# AE402FA0E5597LE0_CM55_HP_View register map
Vendor: Alif Semiconductor; Series: E4; File version: 1.0
CPU: CM55 r1p0, selectable endian, MPU, FPU, double-precision FPU, DSP, VTOR, 8 interrupt priority bits, 1 SAU regions
Registers are 32-bit, read-write, reset 0x0 unless marked. A register's access mark holds for its fields unless they carry their own. Offsets are from the block's base; [hi:lo] are bit positions.

## SDMMC (part 1 of 2)
Base 0x48102000
0x00 SDMMC_SDMASA_R — SDMA System Address Register
  [31:0] BLOCKCNT_SDMASA — 32-bit Block Count-SDMA System Address. SDMMC_HOST_CTRL2_R[HOST_VER4_ENABLE] = 0x0: The BLOCKCNT_SDMASA bit field contains the system memory address for an SDMA transfer in the 32-bit addressing Mode. When the host controller stops an SDMA transfer, this bit field points to the system address of the next contiguous data position. It can be accessed only if no transaction is executing. Reading this bit field during data transfers may return invalid value. 32-bit Block Count SDMMC_HOST_CTRL2_R[HOST_VER4_ENABLE] = 0x1: From the host controller version 4.10 specification, the BLOCKCNT_SDMASA bit field is redefined as 32-bit Block Count. The host controller decrements the block count of this bit field for every block transfer and the data transfer stops when the count reaches zero. This bit field must be accessed when no transaction is executing. Reading this bit field during data transfers may return invalid value. Note: For the SDMMC_HOST_CTRL2_R[HOST_VER4_ENABLE] = 0x0, the host driver does not program the system address in this bit field while operating in ADMA mode. The system address must be programmed in the ADMA System Address register (SDMMC_ADMA_SA_LOW_R). For the SDMMC_HOST_CTRL2_R[HOST_VER4_ENABLE] = 0x0, the host driver programs a non-zero 32-bit block count value in this bit field when Auto CMD23 is enabled for non-DMA and ADMA modes. Auto CMD23 cannot be used with SDMA. This bit field must be programmed with a non-zero value for data transfer if the 32-bit Block Count register is used instead of the 16-bit Block Count register (SDMMC_BLOCKCOUNT_R).
    0xFFFFFFFF=4GB-1 Block; 2=2 Blocks; 1=1 Block; 0=Stop count
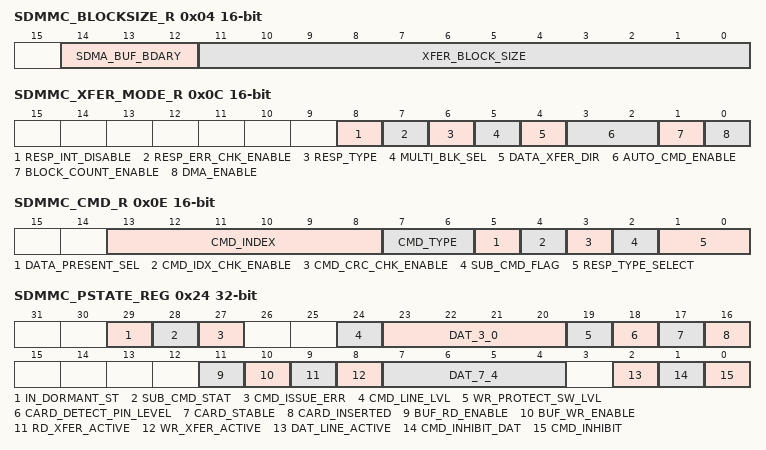
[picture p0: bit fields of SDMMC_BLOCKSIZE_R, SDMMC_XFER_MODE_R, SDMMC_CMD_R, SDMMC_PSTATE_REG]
0x04 SDMMC_BLOCKSIZE_R 16-bit — Block Size Register
  [14:12] SDMA_BUF_BDARY — SDMA Buffer Boundary. These bits specify the size of a contiguous buffer in the system memory. The SDMA transfer waits at every boundary specified by these bits and the host controller generates the DMA interrupt to request the host driver to update the SDMMC_SDMASA_R register.
    0=4KB Bytes SDMA buffer boundary; 1=8KB Bytes SDMA buffer boundary; 2=16KB Bytes SDMA buffer boundary; 3=32KB Bytes SDMA buffer boundary; 4=64KB Bytes SDMA buffer boundary; 5=128KB Bytes SDMA buffer boundary; 6=256KB Bytes SDMA buffer boundary; 7=512KB Bytes SDMA buffer boundary
  [11:0] XFER_BLOCK_SIZE — Transfer Block Size. These bits specify the block size of data transfers. In case of memory, it is set to 512 bytes. It can be accessed only if no transaction is executing. Read operations during transfers may return an invalid value, and write operations are ignored. Following are the values for this bit field:
    1=1 Byte; 2=2 Bytes; 3=3 Bytes; 0x1FF=511 Byte; 0x200=512 Bytes; 0x800=2048 Bytes
0x06 SDMMC_BLOCKCOUNT_R 16-bit — 16-bit Block Count Register
  [15:0] BLOCK_CNT — 16-bit Block Count. If the SDMMC_HOST_CTRL2_R[HOST_VER4_ENABLE] bit is set to 0x0 or this bit field is set to non-zero, the 16-bit Block Count register is selected. If the SDMMC_HOST_CTRL2_R[HOST_VER4_ENABLE] bit is set to 0x1 and this bit field is set to zero, the 32-bit Block Count register is selected.
    0=Stop count; 1=1 Block; 2=2 Blocks; 0xFFFF=65535 Blocks
0x08 SDMMC_ARGUMENT_R — Argument Register
  [31:0] ARGUMENT — Command Argument. These bits specify the SD or eMMC command argument that is specified in bits 39 to 8 of the Command Format.
0x0C SDMMC_XFER_MODE_R 16-bit — Transfer Mode Register
  [8] RESP_INT_DISABLE — Response Interrupt Disable. The host controller supports a response check function to avoid the overhead of response error checking by the host driver. Response types of only R1 and R5 can be checked by the host controller. If the host driver checks the response error, this bit should be set to 0x0 and wait for Command Complete interrupt and then check the respective response register (SDMMC_RESP01_R, SDMMC_RESP23_R, SDMMC_RESP45_R, and SDMMC_RESP67_R). If the host controller checks the response error, this bit and the SDMMC_XFER_MODE_R[RESP_ERR_CHK_ENABLE] bit should be set to 0x1. The Command Complete interrupt is disabled by this bit regardless of the Command Complete Signal Enable (SDMMC_NORMAL_INT_SIGNAL_EN_R[CMD_COMPLETE_SIGNAL_EN]).
    0=Response interrupt is enabled; 1=Response interrupt is disabled
  [7] RESP_ERR_CHK_ENABLE — Response Error Check Enable. The host controller supports response check function to avoid overhead of response error check by the host driver. Response types of only R1 and R5 can be checked by the Controller. If the host controller checks the response error, this bit and the SDMMC_XFER_MODE_R[RESP_INT_DISABLE] bit should be set to 0x1. If an error is detected, the Response Error interrupt is generated (see SDMMC_ERROR_INT_STAT_R[RESP_ERR] bit). Note: Response error check must not be enabled for any response types other than R1 and R5.
    0=Response Error Check is disabled; 1=Response Error Check is enabled
  [6] RESP_TYPE — Response Type R1/R5. This bit selects either R1 or R5 as a response type when the Response Error Check is selected (SDMMC_XFER_MODE_R[RESP_ERR_CHK_ENABLE]). Error statuses checked in R1: - OUT_OF_RANGE - ADDRESS_ERROR - BLOCK_LEN_ERROR - WP_VIOLATION - CARD_IS_LOCKED - COM_CRC_ERROR - CARD_ECC_FAILED - CC_ERROR - ERROR - COM_CRC_ERROR - ERROR - FUNCTION_NUMBER - OUT_OF_RANGE
    0=R1 (Memory); 1=R5 (SDIO)
  [5] MULTI_BLK_SEL — Multi/Single Block Select. This bit is set when issuing multiple-block transfer commands using the DAT line. If this bit is set to 0x0, it is not necessary to set the SDMMC_BLOCKCOUNT_R register.
    0=Single block; 1=Multiple block
  [4] DATA_XFER_DIR — Data Transfer Direction Select. This bit defines the direction of the DAT line data transfers. This bit is set to 0x1 by the host driver to transfer data from the SD or eMMC card to the host controller and it is set to 0x0 for all other commands.
    0=Write (Host to Card); 1=Read (Card to Host)
  [3:2] AUTO_CMD_ENABLE — Auto Command Enable. This bit field determines use of Auto Command functions.
    0=Auto Command disabled; 1=Auto CMD12 enable; 2=Auto CMD23 enable; 3=Auto CMD Auto select
  [1] BLOCK_COUNT_ENABLE — Block Count Enable. This bit is used to enable the SDMMC_BLOCKCOUNT_R register, which is relevant for multiple block transfers. If this bit is set to 0x0, the SDMMC_BLOCKCOUNT_R register is disabled, which is useful in executing an infinite transfer.
    0=Disable; 1=Enable
  [0] DMA_ENABLE — DMA Enable. This bit enables the DMA functionality. If this bit is set to 0x1, a DMA operation begins when the host driver writes to the SDMMC_CMD_R register. One of the DMA modes can be selected by setting the SDMMC_HOST_CTRL1_R[DMA_SEL] bit field.
    0=No data transfer or non-DMA data transfer; 1=DMA data transfer
0x0E SDMMC_CMD_R 16-bit — Command Register
  [13:8] CMD_INDEX — Command Index. These bits are set to the command number that is specified in bits 45 to 40 of the Command Format.
  [7:6] CMD_TYPE — Command Type. These bits indicate the command type. Note: While issuing Abort CMD (using CMD12/CMD52) or reset CMD (using CMD0/CMD52), these bits must be set to 0x3. In case CMD0 is used for initialization, set this bit field to 0x0.
    0=Normal; 1=Suspend; 2=Resume; 3=Abort
  [5] DATA_PRESENT_SEL — Data Present Select. This bit is set to 0x1 to indicate that data is present and that the data is transferred using the DAT line. This bit is set to 0x0 in the following instances: - Command using the CMD line - Command with no data transfer but using busy signal on the DAT[0] line - Resume Command
    0=No data present; 1=Data present
  [4] CMD_IDX_CHK_ENABLE — Command Index Check Enable. This bit enables the host controller to check the index field in the response to verify if it has the same value as the command index. If the value is not the same, it is reported as a Command Index error. Note: Index Check enable must be set to 0x0 for the command with no response, R2 response, R3 response and R4 response.
    0=Disable; 1=Enable
  [3] CMD_CRC_CHK_ENABLE — Command CRC Check Enable. This bit enables the host controller to check the CRC field in the response. If an error is detected, it is reported as a Command CRC error. Note: CRC Check enable must be set to 0x0 for the command with no response, R3 response, and R4 response.
    0=Disable; 1=Enable
  [2] SUB_CMD_FLAG — Sub-command Flag. This bit distinguishes between a main command and a Sub-command.
    0=Main command; 1=Sub-command
  [1:0] RESP_TYPE_SELECT — Response Type Select. This bit field indicates the type of response expected from the card.
    0=No response; 1=Response length 136; 2=Response length 48; 3=Response length 48; Check busy after response
0x10 SDMMC_RESP01_R ro — Response Register 0/1
  [31:0] RESP01 — Command Response. These bits reflect 39 to 8 bits of the SD or eMMC response field.
0x14 SDMMC_RESP23_R ro — Response Register 2/3
  [31:0] RESP23 — Command Response. These bits reflect 71 to 40 bits of the SD or eMMC response field.
0x18 SDMMC_RESP45_R ro — Response Register 4/5
  [31:0] RESP45 — Command Response. These bits reflect 103 to 72 bits of the SD or eMMC response field.
0x1C SDMMC_RESP67_R ro — Response Register 6/7
  [31:0] RESP67 — Command Response. These bits reflect bits 135 to 104 of the SD or eMMC response field.
0x20 SDMMC_BUF_DATA_R — Buffer Data Port Register
  [31:0] BUF_DATA — Buffer Data. These bits enable access to the host controller packet buffer.
0x24 SDMMC_PSTATE_REG ro — Present State Register
  [29] IN_DORMANT_ST — In Dormant Status. for both SD or eMMC modes, this bit always returns 0x0.
    0=Not in Dormant state; 1=In Dormant state
  [28] SUB_CMD_STAT — Sub-command Status. This bit is used to distinguish between a main command and a Sub-command status.
    0=Main command status; 1=Sub-command status
  [27] CMD_ISSUE_ERR — Command Not Issued by Error. This bit is set if a command cannot be issued after setting the SDMMC_CMD_R register due to an error except the Auto CMD12 error.
    0=No error for issuing a command; 1=Command cannot be issued
  [24] CMD_LINE_LVL — Command-Line Signal Level. This bit is used to check the CMD line level to recover from errors and for debugging. These bits reflect the value of the SD_CMD input signal.
  [23:20] DAT_3_0 — DAT[3-0] Line Signal Level. This bit is used to check the DAT line level for error recovery and debugging. These bits reflect the value of the SD_D[0-3] input (lower nibble) signals.
  [19] WR_PROTECT_SW_LVL — Write Protect Switch Pin Level. This bit is supported only for memory and combo cards. This bit reflects the synchronized value of the card write protect signal.
    0=Write protected; 1=Write enabled
  [18] CARD_DETECT_PIN_LEVEL — Card Detect Pin Level. This bit reflects the inverse synchronized value of the card detect signal.
    0=No card present; 1=Card present
  [17] CARD_STABLE — Card Stable. This bit indicates the stability of the Card Detect Pin Level (see CARD_DETECT_PIN_LEVEL bit). A card is not detected if this bit is set to 0x1 and the value of the CARD_INSERTED bit is 0x0.
    0=Reset or debouncing; 1=No card or Inserted
  [16] CARD_INSERTED — Card Inserted. This bit indicates whether a card has been inserted. The host controller debounces this signal so that host driver need not wait for it to stabilize.
    0=Reset, debouncing, or no card; 1=Card inserted
  [11] BUF_RD_ENABLE — Buffer Read Enable. This bit is used for non-DMA transfers. This bit is set if valid data exists in the Host buffer.
    0=Read disable; 1=Read enable
  [10] BUF_WR_ENABLE — Buffer Write Enable. This bit is used for non-DMA transfers. This bit is set if space is available for writing data.
    0=Write disable; 1=Write enable
  [9] RD_XFER_ACTIVE — Read Transfer Active. This bit indicates whether a read transfer is active for both SD or eMMC modes.
    0=No valid data; 1=Transferring data
  [8] WR_XFER_ACTIVE — Write Transfer Active. This status indicates whether a write transfer is active for both SD or eMMC modes.
    0=No valid data; 1=Transferring data
  [7:4] DAT_7_4 — DAT[7-4] Line Signal Level. This bit is used to check the DAT line level to recover from errors and for debugging. These bits reflect the value of the SD_D[7-4] input (upper nibble) signals.
  [2] DAT_LINE_ACTIVE — DAT Line Active (SD or eMMC mode only). This bit indicates whether one of the DAT lines on the SD or eMMC bus is in use. In the case of read transactions, this bit indicates whether a read transfer is executing on the SD or eMMC bus. In the case of write transactions, this bit indicates whether a write transfer is executing on the SD or eMMC bus. For a command with busy, this status indicates whether the command executing busy is executing on an SD or eMMC bus.
    0=DAT line inactive; 1=DAT line active
  [1] CMD_INHIBIT_DAT — Command Inhibit for DAT line This bit is applicable for both SD or eMMC modes and is generated if either DAT line active or Read transfer active is set to 0x1. If this bit is set to 0x0, it indicates that the host controller can issue subsequent SD or eMMC commands.
    0=Can issue command which used DAT line; 1=Cannot issue command which used DAT line
  [0] CMD_INHIBIT — Command Inhibit for CMD line This bit indicates the following: SD or eMMC mode: If this bit is set to 0x0, it indicates that the CMD line is not in use and the host controller can issue an SD or eMMC command using the CMD line. This bit is set when the SDMMC_CMD_R register is written. This bit is cleared when the command response is received. This bit is not cleared by the response of auto CMD12/CMD23 but cleared by the response of read/write command.
    0=Host controller is ready to issue a command; 1=Host controller is not ready to issue a command
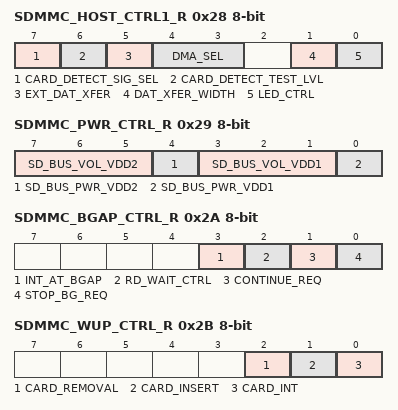
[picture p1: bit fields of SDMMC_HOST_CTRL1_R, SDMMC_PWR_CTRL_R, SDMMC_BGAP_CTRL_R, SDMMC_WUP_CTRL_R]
0x28 SDMMC_HOST_CTRL1_R 8-bit — Host Control 1 Register
  [7] CARD_DETECT_SIG_SEL — Card Detect Signal Selection. This bit selects a source for card detection. When the source for the card detection is switched, the interrupt must be disabled during the switching period.
    0=Card detect signal is selected (for normal use); 1=Card detect test level is selected (for test purpose)
  [6] CARD_DETECT_TEST_LVL — Card Detect Test Level. This bit is enabled while the SDMMC_HOST_CTRL1_R[CARD_DETECT_SIG_SEL] bit is set to 0x1 and it indicates whether a card inserted or not.
    0=No card; 1=Card inserted
  [5] EXT_DAT_XFER — Extended Data Transfer Width. This bit controls 8-bit bus width mode of embedded device.
    0=Bus width is selected by the SDMMC_HOST_CTRL1_R [DAT_XFER_WIDTH] bit; 1=8-bit bus width
  [4:3] DMA_SEL — DMA Select. This field is used to select the DMA type. When the SDMMC_HOST_CTRL2_R[HOST_VER4_ENABLE] bit is set to 0x1: 0x0: SDMA is selected 0x1: Reserved 0x2: ADMA2 is selected 0x3: ADMA2 or ADMA3 is selected When the SDMMC_HOST_CTRL2_R[HOST_VER4_ENABLE] bit is set to 0x0: 0x0: SDMA is selected 0x1: Reserved 0x2: 32-bit Address ADMA2 is selected 0x3: 64-bit Address ADMA2 is selected
  [1] DAT_XFER_WIDTH — Data Transfer Width. For both SD or eMMC modes, this bit selects the data transfer width of the host controller. The host driver sets it to match the data width of the SD or eMMC card.
    0=1-bit mode; 1=4-bit mode
  [0] LED_CTRL — LED Control. This bit is used to caution not to remove the card while the SD card is being accessed. The value is reflected on the led control signal.
    0=LED off; 1=LED on
0x29 SDMMC_PWR_CTRL_R 8-bit — Power Control Register
  [7:5] SD_BUS_VOL_VDD2 — SD Bus Voltage Select for VDD2. This field is irrelevant for SD and eMMC card.
    0=VDD2 Not Supported; 5=1.8 V
  [4] SD_BUS_PWR_VDD2 — SD Bus Power for VDD2. This is irrelevant for SD and eMMC card.
    0=Power off; 1=Power on
  [3:1] SD_BUS_VOL_VDD1 — SD Bus Voltage Select for VDD1/eMMC. These bits enable the host driver to select the voltage level for an SD or eMMC card. Before setting these bits, the host driver checks the Voltage Support bits in the Capabilities register (SDMMC_CAPABILITIES1_R and SDMMC_CAPABILITIES2_R). If an unsupported voltage is selected, the Host System does not supply the SD Bus voltage. The value set in this field is available on the SDMMC output signal, which is used by the voltage switching circuitry. SD Bus Voltage Select options: 0x0 - 0x4: Reserved 0x5: 1.8 V (Typical) for Embedded 0x6: 3.0 V (Typical) 0x7: 3.3 V (Typical) eMMC Bus Voltage Select options: 0x0 - 0x4: Reserved 0x5: 1.2 V (Typical) 0x6: 1.8 V (Typical) 0x7: 3.3 V (Typical)
  [0] SD_BUS_PWR_VDD1 — SD Bus Power for VDD1. It can be used to control the VDD1 power supply of the card. Before setting this bit, the SD host driver sets the SD Bus Voltage Select bit. If the host controller detects a No Card state, this bit is cleared. In SD mode, if this bit is cleared, the host controller stops the SD clock by clearing the SDMMC_CLK_CTRL_R[SD_CLK_IN] bit.
    0=Power off; 1=Power on
0x2A SDMMC_BGAP_CTRL_R 8-bit — Block Gap Control Register
  [3] INT_AT_BGAP — Interrupt at Block Gap. This bit is valid only in the 4-bit mode of an SDIO card and is used to select a sample point in the interrupt cycle. Setting this bit to 0x1 enables interrupt detection at the block gap for a multiple block transfer.
    0=Disabled; 1=Enabled
  [2] RD_WAIT_CTRL — Read Wait Control. This bit is used to enable the read wait protocol to stop read data using SD_D[2] line if the card supports read wait. Otherwise, the host controller has to stop the card clock to hold the read data.
    0=Disable read wait control; 1=Enable read wait control
  [1] CONTINUE_REQ — Continue Request. This bit is used to restart the transaction, which was stopped using the Stop at Block Gap Request (SDMMC_BGAP_CTRL_R[STOP_BG_REQ]). The host controller automatically clears this bit when the transaction restarts. If stop at block gap request is set to 0x1, any write to this bit is ignored.
    0=No affect; 1=Restart
  [0] STOP_BG_REQ — Stop at Block Gap Request. This bit is used to stop executing read and write transactions at the next block gap for non-DMA, SDMA, and ADMA transfers.
    0=Transfer; 1=Stop
0x2B SDMMC_WUP_CTRL_R 8-bit — Wakeup Control Register
  [all] fields
    0=Disable; 1=Enable
  [2] CARD_REMOVAL — Wakeup Event Enable on SD Card Removal. This bit enables wakeup event through Card Removal assertion in the SDMMC_NORMAL_INT_STAT_EN_R register. For the SDIO card, wake up support in the Card Information Structure (CIS) register does not affect this bit.
  [1] CARD_INSERT — Wakeup Event Enable on SD Card Insertion. This bit enables wakeup event through Card Insertion assertion in the SDMMC_NORMAL_INT_STAT_EN_R register. Wake Up Support in CIS register does not affect this bit.
  [0] CARD_INT — Wakeup Event Enable on Card Interrupt. This bit enables wakeup event through a Card Interrupt assertion in the SDMMC_NORMAL_INT_STAT_EN_R register. This bit can be set to 0x1 if Wake Up Support in CIS register is set to 0x1.
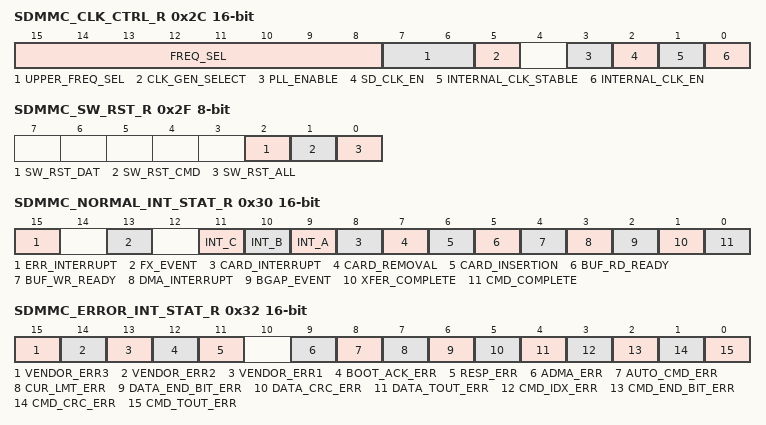
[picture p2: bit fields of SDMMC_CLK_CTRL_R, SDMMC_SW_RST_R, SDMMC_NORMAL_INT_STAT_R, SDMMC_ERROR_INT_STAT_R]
0x2C SDMMC_CLK_CTRL_R 16-bit — Clock Control Register
  [15:8] FREQ_SEL — SD_CLK Frequency Select. These bits are used to select the frequency of the SD_CLK signal. These bits depend on setting of the SDMMC_HOST_CTRL2_R[PRESET_VAL_ENABLE] bit. If the SDMMC_HOST_CTRL2_R[PRESET_VAL_ENABLE] = 0x0, these bits are set by the host driver. If the SDMMC_HOST_CTRL2_R[PRESET_VAL_ENABLE] = 0x1, these bits are automatically set to a value specified in one of the Preset Value register. 10-bit Divided Clock Mode: 0x000: Base clock 0x001: 1/2 Divided clock 0x002: 1/4 Divided clock ... N: 1/2N Divided clock ... 0x3FF: 1/2046 Divided clock Programmable Clock mode (enables the Host System to select a fine grain SD clock frequency): 0x000: Base clock x M 0x001: Base clock x M/2 0x002: Base clock x M/3 ... N-1: Base clock x M/N ... 0x3FF: Base clock x M/1024
  [7:6] UPPER_FREQ_SEL — These bits specify the upper 2 bits of 10-bit SD_CLK Frequency Select control (FREQ_SEL bit field).
  [5] CLK_GEN_SELECT — Clock Generator Select. This bit is used to select the clock generator mode in SD_CLK Frequency Select bit field (FREQ_SEL). If the SDMMC_HOST_CTRL2_R[PRESET_VAL_ENABLE] = 0x0, this bit is set by the host driver. If the SDMMC_HOST_CTRL2_R[PRESET_VAL_ENABLE] = 0x1, this bit is automatically set to a value specified in one of the Preset Value registers.
    0=Divided clock mode; 1=Programmable clock mode
  [3] PLL_ENABLE — PLL Enable. This bit is used to activate the PLL (applicable when the SDMMC_HOST_CTRL2_R[HOST_VER4_ENABLE] = 0x1). When the SDMMC_HOST_CTRL2_R[HOST_VER4_ENABLE] = 0x0, the INTERNAL_CLK_EN bit may be used to activate PLL. Note: If this bit is not used to active the PLL when the SDMMC_HOST_CTRL2_R[HOST_VER4_ENABLE] = 0x1, it is recommended to set it to 0x1.
    0=PLL is in low power mode; 1=PLL is enabled
  [2] SD_CLK_EN — SD or eMMC Clock Enable. This bit stops the SD_CLK when is set to 0x0. The FREQ_SEL bit field can be changed when this bit is set to 0x0.
    0=Disable providing SD_CLK; 1=Enable providing SD_CLK
  [1] INTERNAL_CLK_STABLE ro — Internal Clock Stable. This bit enables the host driver to check the clock stability twice after the SDMMC_CLK_CTRL_R[INTERNAL_CLK_EN] bit is set and after both INTERNAL_CLK_EN and PLL_ENABLE bits are set.
    0=Not ready; 1=Ready
  [0] INTERNAL_CLK_EN — Internal Clock Enable. This bit is set to 0x0 when the host driver is not using the host controller or the host controller awaits a wakeup interrupt. The host controller must stop its internal clock to enter a very low power state. However, registers can still be read and written to. Note: If this bit is not used to control the internal clock (base clock and master clock), it is recommended to set it to 0x1.
    0=Stop; 1=Oscillate
0x2E SDMMC_TOUT_CTRL_R 8-bit — Timeout Control Register
  [3:0] TOUT_CNT — Data Timeout Counter Value. This value determines the interval by which DAT line timeouts are detected. The timeout clock frequency is generated by dividing the base clock (BCLK) value by this value. When setting this bit field, the user should prevent inadvertent timeout events by clearing the SDMMC_ERROR_INT_STAT_EN_R[DATA_TOUT_ERR_STAT_EN] bit. The values for these bits are: Note: During a boot operating in an eMMC mode, an application must configure the boot data timeout value (approximately 1 second) in this bit field.
    0=TMCLK x 2^13; 1=TMCLK x 2^14; 14=TMCLK x 2^27
0x2F SDMMC_SW_RST_R 8-bit — Software Reset Register
  [all] fields
    0=Work; 1=Reset
  [2] SW_RST_DAT — Software Reset for DAT line. This bit is used in SD or eMMC modes and it resets only a part of the data circuit and the DMA circuit. The following registers and bits are cleared by this bit: SDMMC_BUF_DATA_R register: - Buffer is cleared and initialized. SDMMC_PSTATE_REG register: - Buffer Read Enable - Buffer Write Enable - Read Transfer Active - Write Transfer Active - DAT Line Active - Command Inhibit (DAT) SDMMC_BGAP_CTRL_R register: - Continue Request - Stop at Block Gap Request SDMMC_NORMAL_INT_STAT_EN_R register: - Buffer Read Ready - Buffer Write Ready - DMA Interrupt - Block Gap Event - Transfer Complete
  [1] SW_RST_CMD — Software Reset for CMD line. This bit resets only a part of the command circuit to enable issuing a command. This reset is effective only for the command issuing circuit (including response error statuses related to Command Inhibit for CMD line control) and does not affect the data transfer circuit. Host controller can continue data transfer even after this reset is executed while handling subcommand-response errors. The following registers and bits are cleared by this bit: - SDMMC_PSTATE_REG register: CMD_INHIBIT bit - SDMMC_NORMAL_INT_STAT_EN_R register: Command Complete bit - SDMMC_ERROR_INT_STAT_EN_R register: Response error statuses related to CMD_INHIBIT bit
  [0] SW_RST_ALL — Software Reset for All. This reset affects the entire host controller except for the card detection circuit. During its initialization, the host driver sets this bit to 0x1 to reset the host controller. All registers are reset except the capabilities register (SDMMC_CAPABILITIES1_R and SDMMC_CAPABILITIES2_R). If this bit is set to 0x1, the host driver must issue reset command and reinitialize the card.
0x30 SDMMC_NORMAL_INT_STAT_R 16-bit — Normal Interrupt Status Register
  [15] ERR_INTERRUPT ro — Error Interrupt. If any of the operating bits in the SDMMC_ERROR_INT_STAT_R register are set, then this bit is set.
    0=No error; 1=Error
  [13] FX_EVENT ro — FX Event. This status is set when R[14] of response register is set to 0x1 and Response Type R1/R5 is set to 0x0 in the SDMMC_XFER_MODE_R register. This interrupt is used with response check function.
    0=No event; 1=FX Event is detected
  [11] INT_C ro — INT_C (Embedded). This bit is set if INT_C is enabled.
  [10] INT_B ro — INT_B (Embedded). This bit is set if INT_B is enabled.
  [9] INT_A ro — INT_A (Embedded). This bit is set if INT_A is enabled.
  [8] CARD_INTERRUPT ro — Card Interrupt. This bit reflects the synchronized value of DAT[1] Interrupt input for SD mode
    0=No card interrupt; 1=Generate card Interrupt
  [7] CARD_REMOVAL — Card Removal. This bit is set when the SDMMC_PSTATE_REG[CARD_INSERTED] transitions from 0x1 (inserted) to 0x0 (removed).
    0=Card state stable or debouncing; 1=Card removed. Write 0x1 to clear.
  [6] CARD_INSERTION — Card Insertion. This bit is set when the SDMMC_PSTATE_REG[CARD_INSERTED] transitions from 0x0 (removed) to 0x1 (inserted).
    0=Card state stable or debouncing; 1=Card inserted. Write 0x1 to clear.
  [5] BUF_RD_READY — Buffer Read Ready. This bit is set if the SDMMC_PSTATE_REG[BUF_RD_ENABLE] bit changes from 0x0 to 0x1.
    0=Not ready to read buffer; 1=Ready to read buffer. Write 0x1 to clear.
  [4] BUF_WR_READY — Buffer Write Ready. This bit is set if the SDMMC_PSTATE_REG[BUF_WR_ENABLE] bit changes from 0x0 to 0x1.
    0=Not ready to write buffer; 1=Ready to write buffer. Write 0x1 to clear.
  [3] DMA_INTERRUPT — DMA Interrupt. This bit is set if the host controller detects the SDMA Buffer Boundary during transfer (refer to SDMMC_BLOCKSIZE_R). In case of ADMA, by setting the Interrupt field in the descriptor table, the host controller generates this interrupt. This interrupt is not generated after a Transfer Complete.
    0=No DMA interrupt; 1=DMA Interrupt is generated. Write 0x1 to clear.
  [2] BGAP_EVENT — Block Gap Event. This bit is set when both read and write transaction is stopped at block gap due to a Stop at Block Gap Request (SDMMC_BGAP_CTRL_R[STOP_BG_REQ]).
    0=No block gap event; 1=Transaction stopped at block gap. Write 0x1 to clear.
  [1] XFER_COMPLETE — Transfer Complete. This bit is set when a read and write transfer and a command with status busy is completed.
    0=Not complete; 1=Command execution is completed. Write 0x1 to clear.
  [0] CMD_COMPLETE — Command Complete. In both SD and eMMC modes, this bit is set when the end bit of a response is detected except for Auto CMD12 and Auto CMD23. This interrupt is not generated when the SDMMC_XFER_MODE_R[RESP_INT_DISABLE] bit is set to 0x1.
    0=No command complete; 1=Command complete. Write 0x1 to clear.
0x32 SDMMC_ERROR_INT_STAT_R 16-bit — Error Interrupt Status Register
  [15] VENDOR_ERR3 ro — Reserved. It always returns 0x0.
  [14] VENDOR_ERR2 ro — Reserved. It always returns 0x0.
  [13] VENDOR_ERR1 ro — Reserved. It always returns 0x0.
  [12] BOOT_ACK_ERR — Boot Acknowledgement Error. This bit is set when there is a timeout for boot acknowledgement or when detecting boot ACK status having a value other than 0x0. This is applicable only when boot acknowledgement is expected in eMMC mode.
    0=No error; 1=Error. Write 0x1 to clear.
  [11] RESP_ERR — Response Error. Host controller version 4.00 supports response error check function to avoid overhead of response error check by the host driver during DMA execution. If the SDMMC_XFER_MODE_R[RESP_ERR_CHK_ENABLE] bit is set to 0x1, the host controller checks R1 or R5 response. If an error is detected in a response, this bit is set to 0x1. This is applicable in SD or eMMC modes.
    0=No error; 1=Error. Write 0x1 to clear.
  [9] ADMA_ERR — ADMA Error. This bit is set when the host controller detects error during ADMA-based data transfer. The error could be due to Error response received from System bus (Master interface)-ADMA3, ADMA2 Descriptors invalid
    0=No error; 1=Error. Write 0x1 to clear.
  [8] AUTO_CMD_ERR — Auto CMD Error. This error status is used by Auto CMD12 and Auto CMD23 in SD or eMMC modes. This bit is set when detecting that any of the bits D00 to D05 in Auto CMD Error Status register has changed from 0x0 to 0x1. D07 is effective in case of Auto CMD12. The Auto CMD Error Status register is valid while this bit is set to 0x1 and may be cleared by clearing of this bit.
    0=No error; 1=Error. Write 0x1 to clear.
  [7] CUR_LMT_ERR — Current Limit Error. By setting the SD Bus Power bit in the SDMMC_PWR_CTRL_R register, the host controller is requested to supply power for the SD Bus. If the host controller supports the Current Limit function, it can be protected from an illegal card by stopping power supply to the card in which case this bit indicates a failure status. A reading of 0x1 for this bit means that the host controller is not supplying power to the SD card due to some failure. A reading of 0x0 for this bit means that the host controller is supplying power and no error has occurred. The host controller may require some sampling time to detect the current limit. If the SDMMC host controller does not support this function, this bit is always set to 0x0.
    0=No error; 1=Power Fail. Write 0x1 to clear.
  [6] DATA_END_BIT_ERR — Data End Bit Error. This error occurs in SD or eMMC modes either when detecting 0x0 at the end bit position of read data that uses the DAT line or at the end bit position of the CRC status.
    0=No error; 1=Error. Write 0x1 to clear.
  [5] DATA_CRC_ERR — Data CRC Error. This error occurs in SD or eMMC modes when detecting CRC error when transferring read data which uses the DAT line, when detecting the Write CRC status having a value of other than 0x0 or when write CRC status timeout.
    0=No error; 1=Error. Write 0x1 to clear.
  [4] DATA_TOUT_ERR — Data Timeout Error. This bit is set in SD or eMMC modes when detecting one of the following timeout conditions: - Busy timeout for R1b, R5b type - Busy timeout after Write CRC status - Write CRC Status timeout - Read Data timeout
    0=No error; 1=Time out. Write 0x1 to clear.
  [3] CMD_IDX_ERR — Command Index Error. This bit is set if a Command Index error occurs in the command response in SD or eMMC modes.
    0=No error; 1=Error. Write 0x1 to clear.
  [2] CMD_END_BIT_ERR — Command End Bit Error. This bit is set when detecting that the end bit of a command response is 0x0 in SD or eMMC modes.
    0=No error; 1=End bit error generated. Write 0x1 to clear.
  [1] CMD_CRC_ERR — Command CRC Error. Command CRC Error is generated in SD or eMMC modes for following two cases. If a response is returned and the Command Timeout Error (SDMMC_ERROR_INT_STAT_R[CMD_TOUT_ERR]) is set to 0x0 (indicating no timeout), this bit is set to 0x1 when detecting a CRC error in the command response. The host controller detects a CMD line conflict by monitoring the CMD line when a command is issued. If the host controller drives the CMD line to 0x1 level, but detects 0x0 level on the CMD line at the next SD clock edge, then the host controller terminates the command (stop driving CMD line) and set this bit to 0x1. The SDMMC_ERROR_INT_STAT_R[CMD_TOUT_ERR] bit is also set to 0x1 to distinguish a CMD line conflict.
    0=No error; 1=CRC error generated. Write 0x1 to clear.
  [0] CMD_TOUT_ERR — Command Timeout Error. in SD or eMMC modes, this bit is set only if no response is returned within 64 SD clock cycles from the end bit of the command. If the host controller detects a CMD line conflict, along with the SDMMC_ERROR_INT_STAT_R[CMD_CRC_ERR] bit, this bit is set to 0x1, without waiting for 64 SD or eMMC card clock cycles.
    0=No error; 1=Time out. Write 0x1 to clear.
